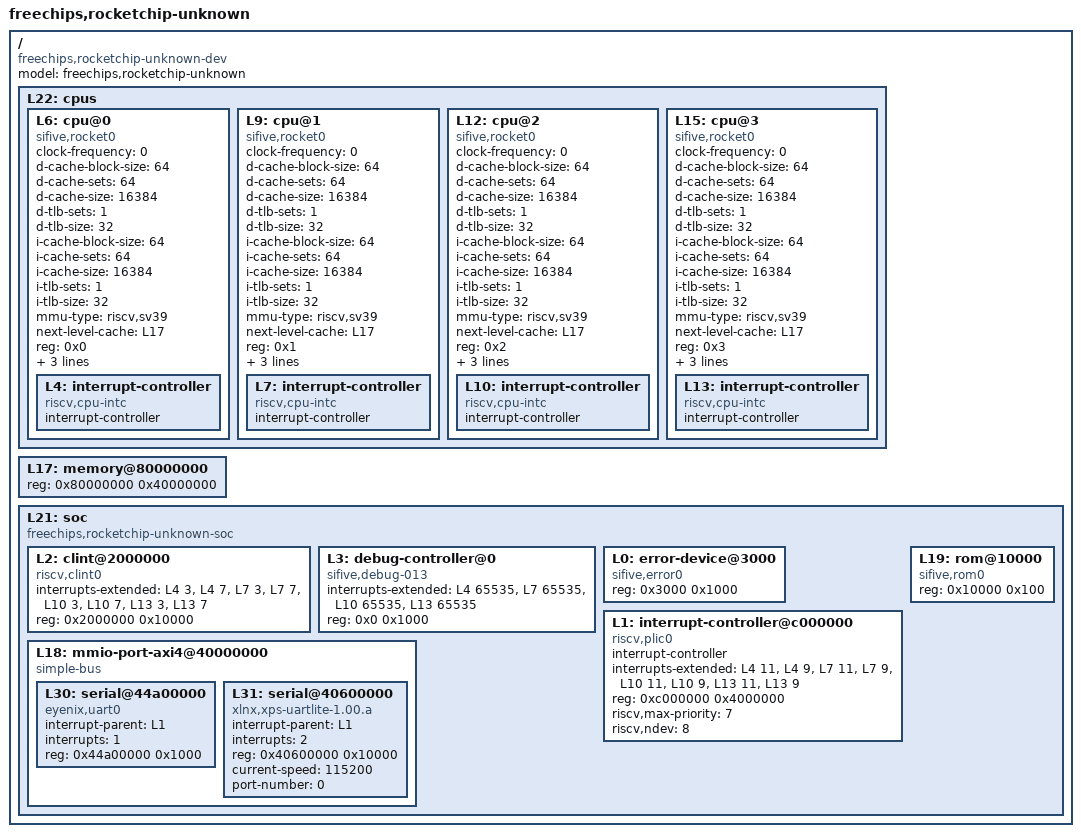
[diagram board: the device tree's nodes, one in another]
/dts-v1/;

/ {
	#address-cells = <1>;
	#size-cells = <1>;
	compatible = "freechips,rocketchip-unknown-dev";
	model = "freechips,rocketchip-unknown";
	L22: cpus {
		#address-cells = <1>;
		#size-cells = <0>;
		L6: cpu@0 {
			clock-frequency = <0>;
			compatible = "sifive,rocket0", "riscv";
			d-cache-block-size = <64>;
			d-cache-sets = <64>;
			d-cache-size = <16384>;
			d-tlb-sets = <1>;
			d-tlb-size = <32>;
			device_type = "cpu";
			i-cache-block-size = <64>;
			i-cache-sets = <64>;
			i-cache-size = <16384>;
			i-tlb-sets = <1>;
			i-tlb-size = <32>;
			mmu-type = "riscv,sv39";
			next-level-cache = <&L17>;
			reg = <0x0>;
			riscv,isa = "rv64imafdc";
			status = "okay";
			timebase-frequency = <1000000>;
			tlb-split;
			L4: interrupt-controller {
				#interrupt-cells = <1>;
				compatible = "riscv,cpu-intc";
				interrupt-controller;
			};
		};
		L9: cpu@1 {
			clock-frequency = <0>;
			compatible = "sifive,rocket0", "riscv";
			d-cache-block-size = <64>;
			d-cache-sets = <64>;
			d-cache-size = <16384>;
			d-tlb-sets = <1>;
			d-tlb-size = <32>;
			device_type = "cpu";
			i-cache-block-size = <64>;
			i-cache-sets = <64>;
			i-cache-size = <16384>;
			i-tlb-sets = <1>;
			i-tlb-size = <32>;
			mmu-type = "riscv,sv39";
			next-level-cache = <&L17>;
			reg = <0x1>;
			riscv,isa = "rv64imafdc";
			status = "okay";
			timebase-frequency = <1000000>;
			tlb-split;
			L7: interrupt-controller {
				#interrupt-cells = <1>;
				compatible = "riscv,cpu-intc";
				interrupt-controller;
			};
		};
		L12: cpu@2 {
			clock-frequency = <0>;
			compatible = "sifive,rocket0", "riscv";
			d-cache-block-size = <64>;
			d-cache-sets = <64>;
			d-cache-size = <16384>;
			d-tlb-sets = <1>;
			d-tlb-size = <32>;
			device_type = "cpu";
			i-cache-block-size = <64>;
			i-cache-sets = <64>;
			i-cache-size = <16384>;
			i-tlb-sets = <1>;
			i-tlb-size = <32>;
			mmu-type = "riscv,sv39";
			next-level-cache = <&L17>;
			reg = <0x2>;
			riscv,isa = "rv64imafdc";
			status = "okay";
			timebase-frequency = <1000000>;
			tlb-split;
			L10: interrupt-controller {
				#interrupt-cells = <1>;
				compatible = "riscv,cpu-intc";
				interrupt-controller;
			};
		};
		L15: cpu@3 {
			clock-frequency = <0>;
			compatible = "sifive,rocket0", "riscv";
			d-cache-block-size = <64>;
			d-cache-sets = <64>;
			d-cache-size = <16384>;
			d-tlb-sets = <1>;
			d-tlb-size = <32>;
			device_type = "cpu";
			i-cache-block-size = <64>;
			i-cache-sets = <64>;
			i-cache-size = <16384>;
			i-tlb-sets = <1>;
			i-tlb-size = <32>;
			mmu-type = "riscv,sv39";
			next-level-cache = <&L17>;
			reg = <0x3>;
			riscv,isa = "rv64imafdc";
			status = "okay";
			timebase-frequency = <1000000>;
			tlb-split;
			L13: interrupt-controller {
				#interrupt-cells = <1>;
				compatible = "riscv,cpu-intc";
				interrupt-controller;
			};
		};
	};
	L17: memory@80000000 {
		device_type = "memory";
		reg = <0x80000000 0x40000000>;
	};
	L21: soc {
		#address-cells = <1>;
		#size-cells = <1>;
		compatible = "freechips,rocketchip-unknown-soc", "simple-bus";
		ranges;
		L2: clint@2000000 {
			compatible = "riscv,clint0";
			interrupts-extended = <&L4 3 &L4 7 &L7 3 &L7 7 &L10 3 &L10 7 &L13 3 &L13 7>;
			reg = <0x2000000 0x10000>;
			reg-names = "control";
		};
		L3: debug-controller@0 {
			compatible = "sifive,debug-013", "riscv,debug-013";
			interrupts-extended = <&L4 65535 &L7 65535 &L10 65535 &L13 65535>;
			reg = <0x0 0x1000>;
			reg-names = "control";
		};
		L0: error-device@3000 {
			compatible = "sifive,error0";
			reg = <0x3000 0x1000>;
		};
		L1: interrupt-controller@c000000 {
			#interrupt-cells = <1>;
			compatible = "riscv,plic0";
			interrupt-controller;
			interrupts-extended = <&L4 11 &L4 9 &L7 11 &L7 9 &L10 11 &L10 9 &L13 11 &L13 9>;
			reg = <0xc000000 0x4000000>;
			reg-names = "control";
			riscv,max-priority = <7>;
			riscv,ndev = <8>;
		};
		L18: mmio-port-axi4@40000000 {
			#address-cells = <1>;
			#size-cells = <1>;
			compatible = "simple-bus";
			ranges = <0x40000000 0x40000000 0x20000000>;
			
			L30: serial@44a00000 {
				compatible = "eyenix,uart0";
				interrupt-parent = <&L1>;
				interrupts = <1>;
				reg = <0x44a00000 0x1000>;
			};
			
			L31: serial@40600000 {
				compatible = "xlnx,xps-uartlite-1.00.a";
				interrupt-parent = <&L1>;
				interrupts = <2>;
				reg = <0x40600000 0x10000>;
				current-speed = <115200>;
				port-number = <0>;
			};
			
		};
		L19: rom@10000 {
			compatible = "sifive,rom0";
			reg = <0x10000 0x100>;
			reg-names = "mem";
		};
	};
};
